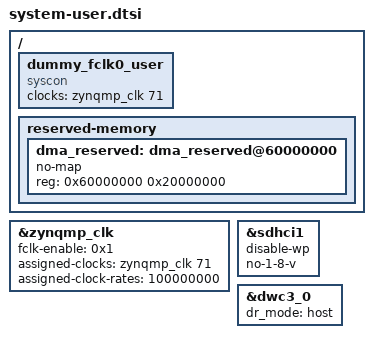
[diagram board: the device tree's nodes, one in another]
/include/ "system-conf.dtsi"
/ {
    dummy_fclk0_user: dummy_fclk0_user {
        compatible = "syscon";  // benign compatibility
        clocks = <&zynqmp_clk 71>;
        clock-names = "aclk";
        status = "okay";
    };
    reserved-memory {
        #address-cells = <1>;
        #size-cells = <1>;
        ranges;

        dma_reserved: dma_reserved@60000000 {
            no-map;
            reg = <0x60000000 0x20000000>;  // 512MB reserved
        };
    };
};
&zynqmp_clk {
    fclk-enable = <0x1>;
    assigned-clocks = <&zynqmp_clk 71>;
    assigned-clock-rates = <100000000>;
};
/* SD */

&sdhci1 {
   disable-wp;
   no-1-8-v;
};

/* USB */
&dwc3_0 {
   status = "okay";
   dr_mode = "host";
};
